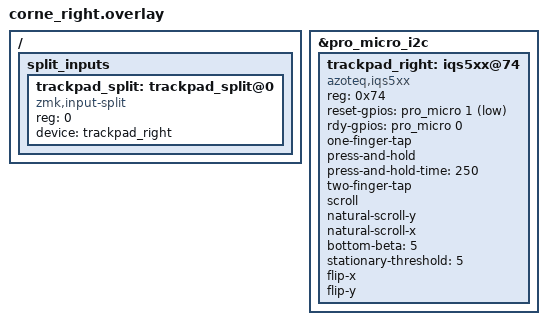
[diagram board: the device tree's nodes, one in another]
/*
 * Configuration Devicetree pour la moitié droite (Peripheral)
 * - Trackpad Azoteq local droit sur I2C (adresse 0x74)
 * - RDY sur TX0 (&pro_micro 0), RST sur RX1 (&pro_micro 1)
 * - Inversion des axes X et Y (flip-x, flip-y)
 * - Transmission des événements vers la moitié centrale via zmk,input-split
 */

#include <dt-bindings/zmk/matrix_transform.h>
#include <dt-bindings/zmk/input_transform.h>
#include <input/processors.dtsi>
#include <dt-bindings/input/input-event-codes.h>

&pro_micro_i2c {
    status = "okay";

    trackpad_right: iqs5xx@74 {
        compatible = "azoteq,iqs5xx";
        reg = <0x74>;
        status = "okay";

        /* Câblage : RST sur RX1 (&pro_micro 1) et RDY sur TX0 (&pro_micro 0) */
        reset-gpios = <&pro_micro 1 GPIO_ACTIVE_LOW>;
        rdy-gpios = <&pro_micro 0 (GPIO_ACTIVE_HIGH | GPIO_PULL_DOWN)>;

        one-finger-tap;
        press-and-hold;
        press-and-hold-time = <250>;
        two-finger-tap;

        scroll;
        natural-scroll-y;
        natural-scroll-x;

        bottom-beta = <5>;
        stationary-threshold = <5>;

        /* Inversion des axes demandée */
        flip-x;
        flip-y;
        /* Décommenter switch-xy si une permutation des axes X et Y est souhaitée selon l'orientation physique : */
        // switch-xy;
    };
};

/ {
    split_inputs {
        #address-cells = <1>;
        #size-cells = <0>;

        trackpad_split: trackpad_split@0 {
            compatible = "zmk,input-split";
            reg = <0>;
            device = <&trackpad_right>;
        };
    };
};
